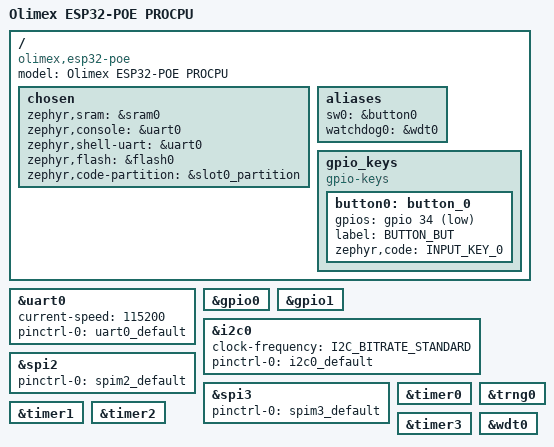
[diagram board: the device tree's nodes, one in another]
/*
 * Copyright (c) 2025
 * SPDX-License-Identifier: Apache-2.0
 */
/dts-v1/;

#include <espressif/esp32/esp32_wroom_32ue_n4.dtsi>
#include "olimex_esp32_poe-pinctrl.dtsi"
#include <zephyr/dt-bindings/input/input-event-codes.h>
#include <espressif/partitions_0x1000_default.dtsi>

/ {
    model = "Olimex ESP32-POE PROCPU";
    compatible = "olimex,esp32-poe";

    chosen {
        zephyr,sram = &sram0;
        zephyr,console = &uart0;
        zephyr,shell-uart = &uart0;
        zephyr,flash = &flash0;
        zephyr,code-partition = &slot0_partition;
    };

    aliases {
        sw0 = &button0;
        watchdog0 = &wdt0;
    };

    gpio_keys {
        compatible = "gpio-keys";
        button0: button_0 {
            gpios = <&gpio 34 GPIO_ACTIVE_LOW>;
            label = "BUTTON_BUT";
            zephyr,code = <INPUT_KEY_0>;
        };
    };
};

&uart0 {
    status = "okay";
    current-speed = <115200>;
    pinctrl-0 = <&uart0_default>;
    pinctrl-names = "default";
};

&gpio0 {
    status = "okay";
};

&gpio1 {
    status = "okay";
};

&i2c0 {
    status = "okay";
    clock-frequency = <I2C_BITRATE_STANDARD>;
    pinctrl-0 = <&i2c0_default>;
    pinctrl-names = "default";
};

&spi2 {
    #address-cells = <1>;
    #size-cells = <0>;
    status = "okay";
    pinctrl-0 = <&spim2_default>;
    pinctrl-names = "default";
};

&spi3 {
    #address-cells = <1>;
    #size-cells = <0>;
    status = "okay";
    pinctrl-0 = <&spim3_default>;
    pinctrl-names = "default";
};

&timer0 {
    status = "okay";
};

&timer1 {
    status = "okay";
};

&timer2 {
    status = "okay";
};

&timer3 {
    status = "okay";
};

&trng0 {
    status = "okay";
};

&wdt0 {
    status = "okay";
};
